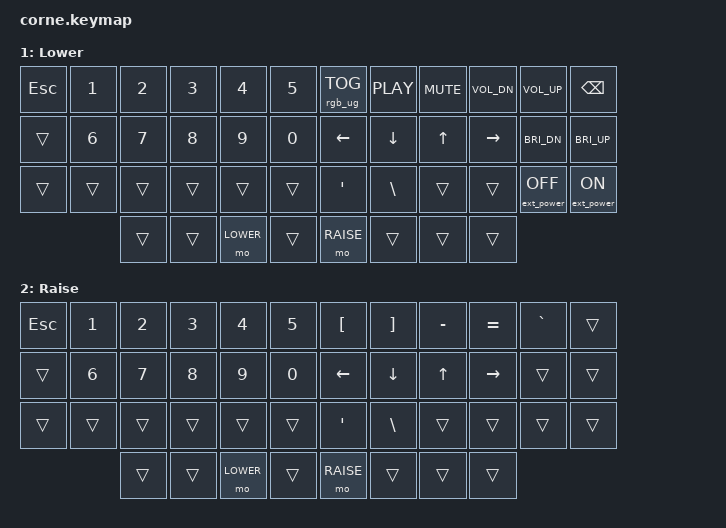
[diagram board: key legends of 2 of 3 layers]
/*
 * Copyright (c) 2020 The ZMK Contributors
 *
 * SPDX-License-Identifier: MIT
 */

#include <behaviors.dtsi>
#include <dt-bindings/zmk/keys.h>
#include <dt-bindings/zmk/bt.h>
#include <dt-bindings/zmk/rgb.h>
#include <dt-bindings/zmk/ext_power.h>

#define BASE 0
#define LOWER 1
#define RAISE 2
#define ADJUST 3

&led_strip {
    chain-length = <27>;
};

/ {

     macros {
        prev_desktop: prev_desktop {
            compatible = "zmk,behavior-macro";
            #binding-cells = <0>;
            bindings = <&macro_press &kp LCTRL>, <&macro_tap &kp LEFT>, <&macro_release &kp LCTRL>;
        };
        next_desktop: next_desktop {
            compatible = "zmk,behavior-macro";
            #binding-cells = <0>;
            bindings = <&macro_press &kp LCTRL>, <&macro_tap &kp RIGHT>, <&macro_release &kp LCTRL>;
        };
        missing_control: missing_control {
            compatible = "zmk,behavior-macro";
            #binding-cells = <0>;
            bindings = <&macro_press &kp LCTRL>, <&macro_tap &kp UP>, <&macro_release &kp LCTRL>;
        };
        application_windows: application_windows {
            compatible = "zmk,behavior-macro";
            #binding-cells = <0>;
            bindings = <&macro_press &kp LCTRL>, <&macro_tap &kp DOWN>, <&macro_release &kp LCTRL>;
        };
        switch_app_window: switch_app_window {
            compatible = "zmk,behavior-macro";
            #binding-cells = <0>;
            bindings = <&macro_press &kp LGUI>, <&macro_tap &kp GRAVE>, <&macro_release &kp LGUI>;
        };

    };

   // Activate ADJUST layer by pressing raise and lower
    conditional_layers {
        compatible = "zmk,conditional-layers";
        adjust_layer {
            if-layers = <LOWER RAISE>;
            then-layer = <ADJUST>;
        };
    };

    keymap {
            compatible = "zmk,keymap";

        default_layer {
            display-name = "Base";
// -----------------------------------------------------------------------------------------
// |  TAB |  Q  |  W  |  E  |  R  |  T  |   |  Y  |  U   |  I  |  O  |  P  | BKSP |
// | CTRL |  A  |  S  |  D  |  F  |  G  |   |  H  |  J   |  K  |  L  |  ;  |  '   |
// | SHFT |  Z  |  X  |  C  |  V  |  B  |   |  N  |  M   |  ,  |  .  |  /  | ESC  |
//                    | GUI | LWR | SPC |   | ENT | RSE  | ALT |
                        bindings = <
&kp TAB   &kp Q  &kp W    &kp E    &kp R     &kp T     &kp Y          &kp U     &kp I         &kp O    &kp P    &kp BSPC
&kp LCTRL &kp A  &kp S    &kp D    &kp F     &kp G     &kp H          &kp J     &kp K         &kp L    &kp SEMI &kp RET
&kp LSHFT &kp Z  &kp X    &kp C    &kp V     &kp B     &kp N          &kp M     &kp COMMA     &kp DOT  &kp FSLH &kp ESC
                                   &kp LALT  &kp LGUI  &mo LOWER      &kp SPACE &mo RAISE     &mo RAISE
                        >;
                };
        lower_layer {
            display-name = "Lower";
            // -----------------------------------------------------------------------------------------
            // |  TAB |  1  |  2  |  3  |  4  |  5  |   |  6  |  7  |  8  |  9  |  0  | BKSP |
            // | BTCLR| BT1 | BT2 | BT3 | BT4 | BT5 |   | LFT | DWN |  UP | RGT |     |      |
            // | SHFT |     |     |     |     |     |   |     |     |     |     |     |      |
            //                    | GUI |     | SPC |   | ENT |     | ALT |

// &kp TAB     &kp N1           &kp N2           &kp N3           &kp N4           &kp N5                               &kp N6    &kp N7    &kp N8    &kp N9     &kp N0  &kp BSPC
// &bt BT_CLR  &bt BT_SEL 0     &bt BT_SEL 1     &bt BT_SEL 2     &bt BT_SEL 3     &bt BT_SEL 4                         &kp LEFT  &kp DOWN  &kp UP    &kp RIGHT  &trans  &trans
// &kp LSHFT   &rgb_ug RGB_TOG  &rgb_ug RGB_EFF  &rgb_ug RGB_BRI  &rgb_ug RGB_BRD  &rgb_ug RGB_COLOR_HSB(172,100,51)    &trans    &trans    &trans    &trans     &trans  &trans
//                                               &kp LGUI         &trans           &kp SPACE                            &kp RET   &trans    &kp RALT
            bindings = <
&kp ESC &kp N1  &kp N2    &kp N3    &kp N4       &kp N5             &rgb_ug RGB_TOG  &kp C_PLAY    &kp C_MUTE  &kp C_VOL_DN  &kp C_VOL_UP      &kp BSPC
&trans  &kp N6  &kp N7    &kp N8    &kp N9       &kp N0             &kp LEFT         &kp DOWN      &kp UP      &kp RIGHT     &kp C_BRI_DN      &kp C_BRI_UP
&trans  &trans  &trans    &trans    &trans       &trans             &kp SQT          &kp BSLH      &trans      &trans        &ext_power EP_OFF &ext_power EP_ON
                &trans    &trans    &mo LOWER    &trans             &mo RAISE        &trans        &trans      &trans
            >;
        };

        raise_layer {
            display-name = "Raise";
            // -----------------------------------------------------------------------------------------
            // |  TAB |  !  |  @  |  #  |  $  |  %  |   |  ^  |  &  |  *  |  (  |  )  | BKSP |
            // | CTRL |     |     |     |     |     |   |  -  |  =  |  [  |  ]  |  \  |  `   |
            // | SHFT |     |     |     |     |     |   |  _  |  +  |  {  |  }  | "|" |  ~   |
            //                    | GUI |     | SPC |   | ENT |     | ALT |
// &kp TAB    &kp EXCL  &kp AT  &kp HASH  &kp DLLR  &kp PRCNT    &kp CARET  &kp AMPS   &kp ASTRK  &kp LPAR  &kp RPAR  &kp BSPC
// &kp LCTRL  &trans    &trans  &trans    &trans    &trans       &kp MINUS  &kp EQUAL  &kp LBKT   &kp RBKT  &kp BSLH  &kp GRAVE
// &kp LSHFT  &trans    &trans  &trans    &trans    &trans       &kp UNDER  &kp PLUS   &kp LBRC   &kp RBRC  &kp PIPE  &kp TILDE
//                              &kp LGUI  &trans    &kp SPACE    &kp RET    &trans     &kp RALT

            bindings = <
&kp ESC &kp N1  &kp N2    &kp N3    &kp N4   &kp N5       &kp LBKT  &kp RBKT   &kp MINUS  &kp EQUAL  &kp GRAVE &trans
&trans  &kp N6  &kp N7    &kp N8    &kp N9   &kp N0       &kp LEFT  &kp DOWN   &kp UP     &kp RIGHT  &trans    &trans
&trans  &trans  &trans    &trans    &trans   &trans       &kp SQT   &kp BSLH   &trans     &trans     &trans    &trans
                          &trans    &trans   &mo LOWER    &trans    &mo RAISE  &trans     &trans     &trans
            >;


        adjust_layer {
            display-name = "Adjust";
// ----------------------------------------------------------------------------------------------------------------------------
// | BTCLR  |  BT1    |  BT2    |   BT3   |   BT4   |   BT5   |                  |      |      |       |      |       |       |
// | EXTPWR | RGB_HUD | RGB_HUI | RGB_SAD | RGB_SAI | RGB_EFF |                  |      |      |       |      |       |       |
// |        | RGB_BRD | RGB_BRI |         |         |         |                  |      |      |       |      |       |       |
// |        |         |         |         |         |         | RGB_TOG | |      |      |      |       |      |       |       |
//                    |         |         |         |         |         | |      |      |      |       |      |
// &kp TAB     &kp N1           &kp N2           &kp N3           &kp N4           &kp N5                               &kp N6    &kp N7    &kp N8    &kp N9     &kp N0  &kp BSPC
// &bt BT_CLR  &bt BT_SEL 0     &bt BT_SEL 1     &bt BT_SEL 2     &bt BT_SEL 3     &bt BT_SEL 4                         &kp LEFT  &kp DOWN  &kp UP    &kp RIGHT  &trans  &trans
// &kp LSHFT   &rgb_ug RGB_TOG  &rgb_ug RGB_EFF  &rgb_ug RGB_BRI  &rgb_ug RGB_BRD  &rgb_ug RGB_COLOR_HSB(172,100,51)    &trans    &trans    &trans    &trans     &trans  &trans
//                                               &kp LGUI         &trans           &kp SPACE                            &kp RET   &trans    &kp RALT

bindings = <
&kp TAB     &kp C_BRI_DN  &kp C_BRI_UP           &kp N3           &kp N4           &kp N5                               &kp N6    &kp C_PLAY    &kp C_MUTE    &kp C_VOL_UP    &kp C_VOL_DN   &kp BSPC
&bt BT_CLR  &bt BT_SEL 0     &bt BT_SEL 1     &bt BT_SEL 2     &bt BT_SEL 3     &bt BT_SEL 4                         &ext_power EP_TOG &rgb_ug RGB_HUD &rgb_ug RGB_HUI &rgb_ug RGB_SAD &rgb_ug RGB_SAI &rgb_ug RGB_EFF
&kp LSHFT   &rgb_ug RGB_TOG  &rgb_ug RGB_EFF  &rgb_ug RGB_BRI  &rgb_ug RGB_BRD  &rgb_ug RGB_COLOR_HSB(172,100,51)    &rgb_ug RGB_BRD &rgb_ug RGB_BRI &trans    &trans     &trans  &trans
                                              &kp LGUI         &trans           &kp SPACE                            &kp RET   &trans    &kp RALT
            >;
        };
    };
};
};
